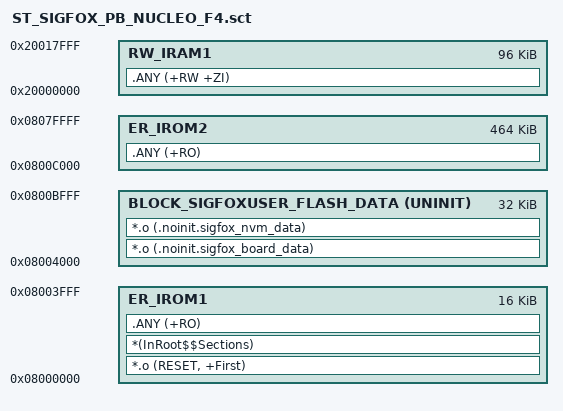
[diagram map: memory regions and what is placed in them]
#! armcc -E
; *************************************************************
; *** Scatter-Loading Description File generated by uVision ***
; *************************************************************

/* Two pages reserved for Sigfox non volatile memory */
#define SECTOR_SIZE 16384
#define FLASH_NVM_DATASIZE 2*SECTOR_SIZE

LR_IROM1 0x08000000 3*SECTOR_SIZE  {    ; load region size_region
  ER_IROM1 (0x08000000) (SECTOR_SIZE)  {  ; load address = execution address
   *.o (RESET, +First)
   *(InRoot$$Sections)
   .ANY (+RO)
  }   
  
  RW_IRAM1 0x20000000 0x00018000  {  ; RW data
   .ANY (+RW +ZI)
  }
}

/* Sigfox non volatile memory */
LR_IROM2 0x08004000 FLASH_NVM_DATASIZE {    ; load region size_region    
  BLOCK_SIGFOXUSER_FLASH_DATA  (0x08004000) UNINIT (FLASH_NVM_DATASIZE) {  ; load address = execution address
  	*.o (.noinit.sigfox_board_data)
  	*.o (.noinit.sigfox_nvm_data)
  }   
}

LR_IROM3 0x0800C000 (0x080000 - 3*SECTOR_SIZE) {    ; load region size_region    
  ER_IROM2 0x0800C000 (0x080000 - 3*SECTOR_SIZE)  {  ; load address = execution address
   .ANY (+RO)
  }
}

